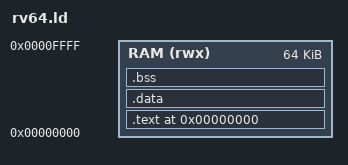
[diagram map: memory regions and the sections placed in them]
ENTRY(_start)

MEMORY
{
    RAM (rwx) : ORIGIN = 0x00000000, LENGTH = 64K
}

SECTIONS
{
    . = ORIGIN(RAM);

    .text : ALIGN(4)
    {
        *(.text.start)
        *(.text*)
        *(.rodata*)
    } > RAM

    .data : ALIGN(8)
    {
        *(.sdata*)
        *(.data*)
    } > RAM

    .bss (NOLOAD) : ALIGN(8)
    {
        __bss_start = .;
        *(.sbss*)
        *(.bss*)
        *(COMMON)
        __bss_end = .;
    } > RAM

    . = ALIGN(16);
    __stack_top = ORIGIN(RAM) + LENGTH(RAM);
    PROVIDE(_stack_top = __stack_top);
}
